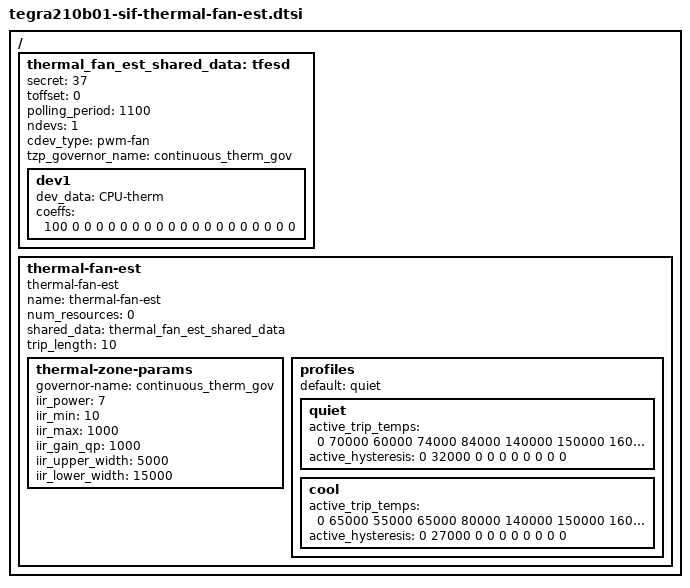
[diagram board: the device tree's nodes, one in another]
/*
 * Copyright (c) 2019, NVIDIA CORPORATION.  All rights reserved.
 *
 * This program is free software; you can redistribute it and/or modify it
 * under the terms and conditions of the GNU General Public License,
 * version 2, as published by the Free Software Foundation.
 *
 * This program is distributed in the hope it will be useful, but WITHOUT
 * ANY WARRANTY; without even the implied warranty of MERCHANTABILITY or
 * FITNESS FOR A PARTICULAR PURPOSE.  See the GNU General Public License for
 * more details.
 */

#include "foster-platforms/tegra210-loki-e-thermal-fan-est.dtsi"

/ {
	thermal_fan_est_shared_data: tfesd {
		secret = <37>;
		toffset = <0>;
		polling_period = <1100>;
		ndevs = <1>;
		cdev_type = "pwm-fan";
		tzp_governor_name = "continuous_therm_gov";

		dev1 {
			dev_data = "CPU-therm";
			coeffs = <100 0 0 0 0 0 0 0 0 0 0 0 0 0 0 0 0 0 0 0>;
		};
	};

	thermal-fan-est {
		name = "thermal-fan-est";
		compatible = "thermal-fan-est";
		status = "okay";
		num_resources = <0>;
		shared_data = <&thermal_fan_est_shared_data>;
		trip_length = <10>;
		thermal-zone-params {
			governor-name = "continuous_therm_gov";
			iir_power = <7>;
			iir_min = <10>;
			iir_max = <1000>;
			iir_gain_qp = <1000>;
			iir_upper_width = <5000>;
			iir_lower_width = <15000>;
		};
		profiles {
			default = "quiet";
			quiet {
				active_trip_temps = <0 70000 60000 74000 84000
					140000 150000 160000 170000 180000>;
				active_hysteresis = <0 32000 0 0 0
					0 0 0 0 0>;
			};
			cool {
				active_trip_temps = <0 65000 55000 65000 80000
					140000 150000 160000 170000 180000>;
				active_hysteresis = <0 27000 0 0 0
					0 0 0 0 0>;
			};
		};
	};
};
